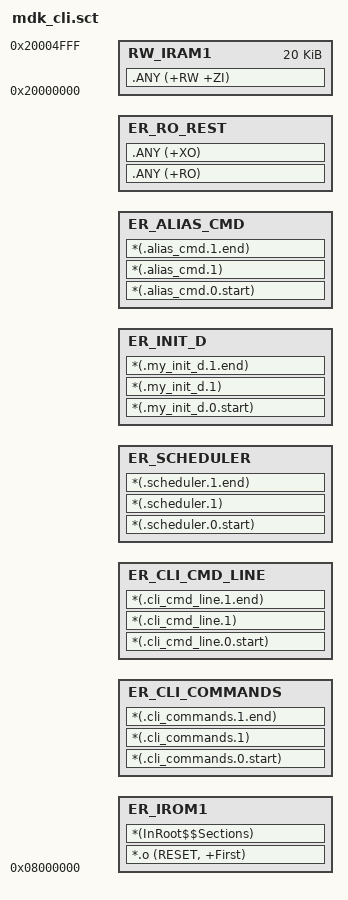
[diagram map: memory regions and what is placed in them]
; *************************************************************
; *** Scatter-Loading Description File for MDK (with CLI)   ***
; *************************************************************
LR_IROM1 0x08000000 0x00010000  {    ; load region size_region
  ER_IROM1 0x08000000  {
    *.o (RESET, +First)
    *(InRoot$$Sections)
  }

  ; -----------------------------------------------------------
  ; 自定义段区域：等价于 cli.ld 中的 KEEP(*(.xxx))
  ; 作为独立 Execution Region 紧跟在 ER_IROM1 之后，
  ; 以便 ARM 链接器为每个段生成独立的 Base/Limit 符号。
  ; 顺序必须位于 .ANY (+RO) 之前，否则会被 .ANY 优先吸收。
  ; -----------------------------------------------------------
  ER_CLI_COMMANDS +0 {
    *(.cli_commands.0.start)
    *(.cli_commands.1)
    *(.cli_commands.1.end)
  }
  ER_CLI_CMD_LINE +0 {
    *(.cli_cmd_line.0.start)
    *(.cli_cmd_line.1)
    *(.cli_cmd_line.1.end)
  }
  ER_SCHEDULER +0 {
    *(.scheduler.0.start)
    *(.scheduler.1)
    *(.scheduler.1.end)
  }
  ER_INIT_D +0 {
    *(.my_init_d.0.start)
    *(.my_init_d.1)
    *(.my_init_d.1.end)
  }
  ER_ALIAS_CMD +0 {
    *(.alias_cmd.0.start)
    *(.alias_cmd.1)
    *(.alias_cmd.1.end)
  }
  ER_RO_REST +0 {
    .ANY (+RO)
    .ANY (+XO)
  }
  RW_IRAM1 0x20000000 0x00005000  {  ; RW data
    .ANY (+RW +ZI)
  }
}
